# cslr_emif_001 register map
Vendor: Texas Instruments
Peripheral module from a debugger description file (folder C5515).
Address unit: 16 bits
Registers are 16-bit, access not given, reset 0x0 unless marked. A register's access mark holds for its fields unless they carry their own. Offsets are as the file gives them; lines under a group give offsets from that group; [hi:lo] are bit positions; {n}, {i} and the like mark numbered series; 'fields as' and 'values as' point back to an identical list; <NAME> marks a mode.

## EMIF — External Memory Interface
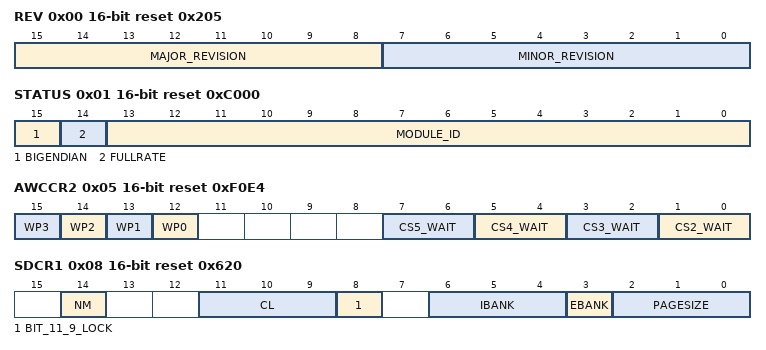
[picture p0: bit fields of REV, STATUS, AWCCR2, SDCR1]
0x00 REV ro reset 0x205 — Revision Register
  [15:8] MAJOR_REVISION — Major revision code for EMIF.
  [7:0] MINOR_REVISION — Minor revision code for EMIF.
0x01 STATUS ro reset 0xC000
  [15] BIGENDIAN — Big endian value, defining big endian mode (data R/W order)
    0=LITTLE (EMIF is running in little endian.); 1=BIG (EMIF is running in big endian.)
  [14] FULLRATE — Full rate status bit. This bit reflects the clock rate being used by the EMIF.
    0=HALFRATE (EMIF is running at half the CPU clock frequency.); 1=FULLRATE (EMIF is running at the same speed as the CPU clock.)
  [13:0] MODULE_ID — Module ID code for EMIF.
0x04 AWCCR1 reset 0x40 — Asynchronous Wait Cycle Configuration Register 1
  [7:0] MEWC rw — Maximum extended wait cycles. The EMIF will wait for a maximum of (MEWC + 1) x 16 clock cycles before it stops inserting asynchronous wait cycles and procedes to the hold period of the access. This setting applies to all the wait pins.
0x05 AWCCR2 reset 0xF0E4 — Asynchronous Wait Cycle Configuration Register 2
  [n+12] WP{n} rw (n=0..3) — EM_WAIT{n} polarity bit. This bit defines the polarity of the EM_WAIT{n} pin.
    0=LOW (Insert wait cycles if wait pin is low.); 1=HIGH (Insert wait cycles if wait pin is high.)
  [2n-3:2n-4] CS{n}_WAIT rw (n=2..5) — Wait pin mapping bits for EMIF CS{n}. By default, each asynchronous chip select space is assigned a wait input pin. You can use the wait pin mapping bits to change the default assignment.
    {v}=WAIT{v} (Use the EM_WAIT{v} pin.) (v=0..3)
0x08 SDCR1 reset 0x620 — SDRAM Configuration Register 1
  [14] NM rw — Narrow mode bit. This bit should always be set to 1. A write to this field will cause the EMIF to start the SDRAM initialization sequence.
  [11:9] CL rw — CAS latency. This field defines the CAS latency to be used when accessing connected SDRAM devices. A 1 must be simultaniously written to the BIT_11_9_LOCK bit field of this register in order to write to the CL bit field. Writing to this field triggers the SDRAM initialization sequence.
    0=RSV0 (Reserved.); 1=RSV1 (Reserved.); 2=TWO (CAS latency set to 2 EM_SDCLK cycles.); 3=THREE (CAS latency set to 3 EM_SDCLK cycles.); {v}=RSV{v} (Reserved.) (v=4..7)
  [8] BIT_11_9_LOCK rw — Bits 11 to 9 lock. CL can only be written if BIT_11_9_LOCK is simultaniously written with a 1. BIT_11_9_LOCK is always read as 0.
    0=NOWRITES (Writes to bits 11 through 9 are disabled.); 1=WRITES (Writes to bits 11 through 9 are enabled.)
  [6:4] IBANK rw — Internal SDRAM Bank size. This field defines number of banks inside the connected SDRAM devices. Writing to this field triggers the SDRAM initialization sequence.
    0=ONE (1 bank SDRAM devices.); 1=TWO (2 bank SDRAM devices.); 2=FOUR (4 bank SDRAM devices.); {v}=RSV{v} (Reserved.) (v=3..7)
  [3] EBANK rw — External chip select setup. Defines whether SDRAM accesses will use 1 or 2 chip select lines. A write to this field will cause the EMIF to start the SDRAM initialization sequence.
    0=ONE (EMIF will use SD_CE0 for all SDRAM accesses.); 1=TWO (EMIF will use SD_CE0 and SD_CE1 for all SDRAM accesses.)
  [2:0] PAGESIZE rw — Page size. This field defines the internal page size of connected SDRAM devices. Writing to this field triggers the SDRAM initialization sequence.
    0=EIGHT (8 column address bits (256 elements per row)); 1=NINE (9 column address bits (512 elements per row)); 2=TEN (10 column address bits (1024 elements per row)); 3=ELEVEN (11 column address bits (2048 elements per row)); {v}=RSV{v} (Reserved.) (v=4..7)
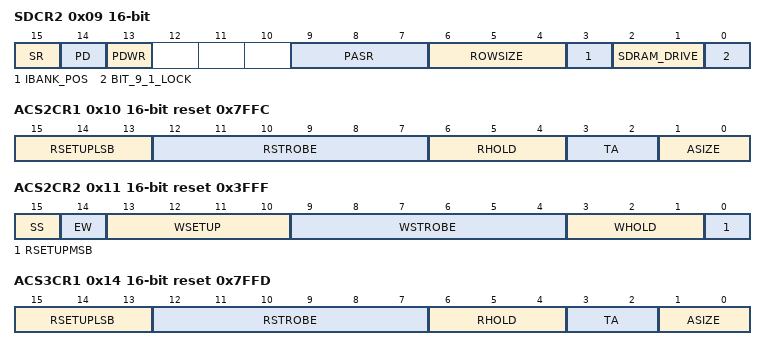
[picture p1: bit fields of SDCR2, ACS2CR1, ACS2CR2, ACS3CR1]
0x09 SDCR2 — SDRAM Configuration Register 2
  [15] SR rw — Self-Refresh mode bit. This bit controls entering and exiting of the Self-Refresh mode. The field should be written using a byte-write to the upper byte of SDCR to avoid triggering the SDRAM initialization sequence.
    0=EXIT (Writing a 0 to this bit will cause connected SDRAM devices and the EMIF to exit the self-refresh mode.); 1=ENTER (Writing a 1 to this bit will cause connected SDRAM devices and the EMIF to enter the self-refresh mode.)
  [14] PD rw — Power down bit. This bit controls entering and exiting of the power down mode. The field should be written using a byte-write to the upper byte of SDCR to avoid triggering the SDRAM initialization sequence. If both SR and PD bits are set, the EMIF will go into Self Refresh.
    0=EXIT (Writing a 0 to this bit will cause connected SDRAM devices and the EMIF to exit the power down mode.); 1=ENTER (Writing a 1 to this bit will cause connected SDRAM devices and the EMIF to enter the power down mode.)
  [13] PDWR rw — Perform refreshes during power down bit. Writign a 1 to this bit will cause EMIF to exit powerdown state and issue and AUTO REFRESH command every time Refresh May level is set.
    0=NOREFR (Do not perform refreshes during power down.); 1=REFR (Perform refreshes during power down.)
  [9:7] PASR rw — Partial array self refresh. These bits get loaded into the Extended Mode Register of a mobile SDR during initialization. A write to this field will cause the EMIF to start the SDRAM initialization sequence. To write to this field you must simultaneously set BIT_9_1_LOCK to 1.
    0=FOUR (4 banks will be refreshed.); 1=TWO (2 banks will be refreshed.); 2=ONE (1 bank will be refreshed.); 3=RSV3 (Reserved.); 4=RSV4 (Reserved.); 5=HALF (Half a bank will be refreshed.); 6=QUARTER (One quarter of a bank will be refreshed.); 7=RSV7 (Reserved.)
  [6:4] ROWSIZE rw — Row size. Defines the number of row address bits of connected SDRAM devices. This field is only used when IBANK_POS is set to 1. A write to this field will cause the EMIF to start the SDRAM initialization sequence. To write to this field you must simultaneously set BIT_9_1_LOCK to 1.
    0=NINE (9 row address bits.); 1=TEN (10 row address bits.); 2=ELEVEN (11 row address bits.); 3=TWELVE (12 row address bits.); 4=THIRTEEN (13 row address bits.); 5=FOURTEEN (14 row address bits.); 6=RSV6 (Reserved.); 7=RSV7 (Reserved.)
  [3] IBANK_POS rw — Internal bank position. This bit specifies the mapping of the logical address to the SDRAM address. A write to this field will cause the EMIF to start the SDRAM initialization sequence. To write to this field you must simultaneously set BIT_9_1_LOCK to 1.
  [2:1] SDRAM_DRIVE rw — SDRAM drive strength. These bits specify the the SDRAM drive strength configuration the EMIF uses while initializing the SDRAM device. A write to this field will cause the EMIF to start the SDRAM initialization sequence. To write to this field you must simultaneously set BIT_9_1_LOCK to 1.
    0=FULL (Full drive strength.); 1=HALF (Half drive strength.); 2=QUARTER (One fourth drive strength.); 3=EIGTH (One eigth drive strength.)
  [0] BIT_9_1_LOCK rw — Bits 9 to 1 lock. Bits 9 through 1 can only be written if BIT_9_1_LOCK is simultaneously written with a 1. BIT_9_1_LOCK is always read as a 0.
    0=NOWRITES (Writes to bits 9 through 1 are disabled.); 1=WRITES (Writes to bits 9 through 1 are enabled.)
0x0C SDRCR reset 0x7D — SDRAM Refresh Control Register
  [12:0] REFRATE rw — Refresh Rate. This field is used to define the SDRAM refresh period in terms of EM_SDCLK cycles. Writing a value < 0x0020 to this field will cause it to be loaded with (2 * T_RFC) + 1 value from SDRAM timing register.
0x10 ACS2CR1 rw reset 0x7FFC — Asynchronous CS2 Configuration Register 1
  [15:13] RSETUPLSB — These bits in conjuction with RSETUPMSB in NCE0CR2 define the read setup timing in EM_SDCLK cycles, minus one cycle.
  [12:7] RSTROBE — Read strobe width in EM_SDCLK cycles, minus one cycle.
  [6:4] RHOLD — Read hold width in EM_SDCLK cycles, minus one cycle.
  [3:2] TA — Minimum turn-around time. This field defines the minimum number of EM_SDCLK cycles between reads and writes, minus one cycle.
  [1:0] ASIZE — Asynchronous data bus width. This field defines the width of the asynchronous device's data bus.
    0=EIGHTBIT (8-bit data bus.); 1=SIXTEENBIT (16-bit data bus.); 2=RSV2 (Reserved.); 3=RSV3 (Reserved.)
0x11 ACS2CR2 rw reset 0x3FFF — Asynchronous CS2 Configuration Register 2
  [15] SS — Select Strobe bit. This bit defines whether the asynchronous interface operates in WE Strobe Mode or Select Strobe Mode.
    0=ENABLED (WE Strobe Mode enabled.); 1=DISABLED (Select Strobe Mode enabled.)
  [14] EW — Extended wait cycles enable bit. This bit defines whether extended wait cycles will be enabled.
    0=DISABLED (Extended wait cycles disabled.); 1=ENABLED (Extended wait cycles enabled.)
  [13:10] WSETUP — Write setup width in EM_SDCLK cycles, minus one cycle.
  [9:4] WSTROBE — Write strobe width in EM_SDCLK cycles, minus one cycle.
  [3:1] WHOLD — Write hold width in EM_SDCLK cycles, minus one cycle.
  [0] RSETUPMSB — These bits in conjuction with RSETUPLSB in NCE0CR1 define the read setup timing in EM_SDCLK cycles, minus one cycle.
0x14 ACS3CR1 rw reset 0x7FFD — Asynchronous CS3 Configuration Register 1
  [15:13] RSETUPLSB — These bits in conjuction with RSETUPMSB in NCE1CR2 define the read setup timing in EM_SDCLK cycles, minus one cycle.
  [12:7] RSTROBE — Read strobe width in EM_SDCLK cycles, minus one cycle.
  [6:4] RHOLD — Read hold width in EM_SDCLK cycles, minus one cycle.
  [3:2] TA — Minimum turn-around time. This field defines the minimum number of EM_SDCLK cycles between reads and writes, minus one cycle.
  [1:0] ASIZE — Asynchronous data bus width. This field defines the width of the asynchronous device's data bus.
    values as ACS2CR1.ASIZE
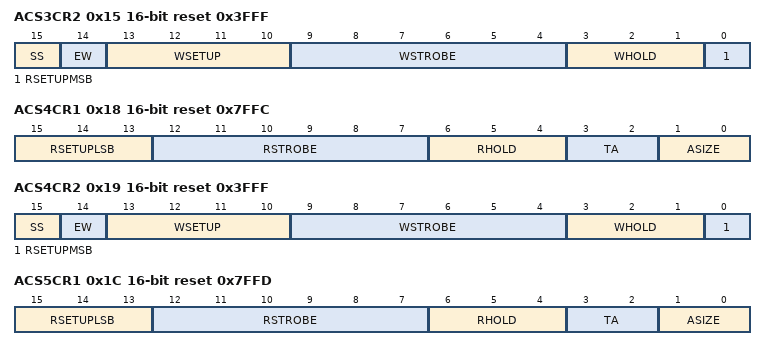
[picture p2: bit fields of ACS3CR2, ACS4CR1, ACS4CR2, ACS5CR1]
0x15 ACS3CR2 rw reset 0x3FFF — Asynchronous CS3 Configuration Register 2
  [15] SS — Select Strobe bit. This bit defines whether the asynchronous interface operates in WE Strobe Mode or Select Strobe Mode.
    values as ACS2CR2.SS
  [14] EW — Extended wait cycles enable bit. This bit defines whether extended wait cycles will be enabled.
    values as ACS2CR2.EW
  [13:10] WSETUP — Write setup width in EM_SDCLK cycles, minus one cycle.
  [9:4] WSTROBE — Write strobe width in EM_SDCLK cycles, minus one cycle.
  [3:1] WHOLD — Write hold width in EM_SDCLK cycles, minus one cycle.
  [0] RSETUPMSB — These bits in conjuction with RSETUPLSB in NCE1CR1 define the read setup timing in EM_SDCLK cycles, minus one cycle.
0x18 ACS4CR1 rw reset 0x7FFC — Asynchronous CS4 Configuration Register 1
  [15:13] RSETUPLSB — These bits in conjuction with RSETUPMSB in ACE0CR2 define the read setup timing in EM_SDCLK cycles, minus one cycle.
  [12:7] RSTROBE — Read strobe width in EM_SDCLK cycles, minus one cycle.
  [6:4] RHOLD — Read hold width in EM_SDCLK cycles, minus one cycle.
  [3:2] TA — Minimum turn-around time. This field defines the minimum number of EM_SDCLK cycles between reads and writes, minus one cycle.
  [1:0] ASIZE — Asynchronous data bus width. This field defines the width of the asynchronous device's data bus.
    values as ACS2CR1.ASIZE
0x19 ACS4CR2 rw reset 0x3FFF — Asynchronous CE0 Configuration Register 2
  [15] SS — Select Strobe bit. This bit defines whether the asynchronous interface operates in WE Strobe Mode or Select Strobe Mode.
    values as ACS2CR2.SS
  [14] EW — Extended wait cycles enable bit. This bit defines whether extended wait cycles will be enabled.
    values as ACS2CR2.EW
  [13:10] WSETUP — Write setup width in EM_SDCLK cycles, minus one cycle.
  [9:4] WSTROBE — Write strobe width in EM_SDCLK cycles, minus one cycle.
  [3:1] WHOLD — Write hold width in EM_SDCLK cycles, minus one cycle.
  [0] RSETUPMSB — These bits in conjuction with RSETUPLSB in ACE0CR1 define the read setup timing in EM_SDCLK cycles, minus one cycle.
0x1C ACS5CR1 rw reset 0x7FFD — Asynchronous CS5 Configuration Register 1
  [15:13] RSETUPLSB — These bits in conjuction with RSETUPMSB in ACE1CR2 define the read setup timing in EM_SDCLK cycles, minus one cycle.
  [12:7] RSTROBE — Read strobe width in EM_SDCLK cycles, minus one cycle.
  [6:4] RHOLD — Read hold width in EM_SDCLK cycles, minus one cycle.
  [3:2] TA — Minimum turn-around time. This field defines the minimum number of EM_SDCLK cycles between reads and writes, minus one cycle.
  [1:0] ASIZE — Asynchronous data bus width. This field defines the width of the asynchronous device's data bus.
    values as ACS2CR1.ASIZE
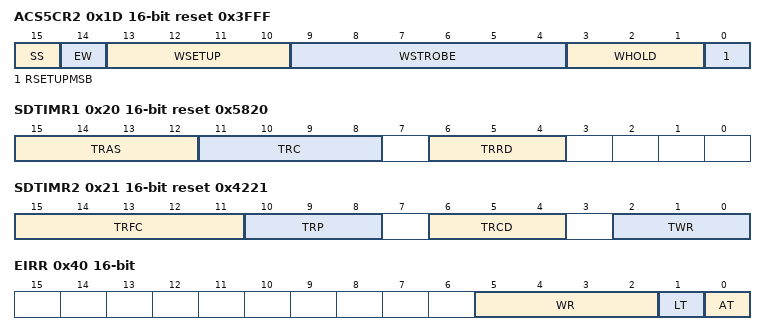
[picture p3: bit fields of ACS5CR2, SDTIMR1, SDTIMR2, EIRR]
0x1D ACS5CR2 rw reset 0x3FFF — Asynchronous CS5 Configuration Register 2
  [15] SS — Select Strobe bit. This bit defines whether the asynchronous interface operates in WE Strobe Mode or Select Strobe Mode.
    values as ACS2CR2.SS
  [14] EW — Extended wait cycles enable bit. This bit defines whether extended wait cycles will be enabled.
    values as ACS2CR2.EW
  [13:10] WSETUP — Write setup width in EM_SDCLK cycles, minus one cycle.
  [9:4] WSTROBE — Write strobe width in EM_SDCLK cycles, minus one cycle.
  [3:1] WHOLD — Write hold width in EM_SDCLK cycles, minus one cycle.
  [0] RSETUPMSB — These bits in conjuction with RSETUPLSB in ACE1CR1 define the read setup timing in EM_SDCLK cycles, minus one cycle.
0x20 SDTIMR1 reset 0x5820 — SDRAM Timing Register 1
  [15:12] TRAS rw — Specifies the Tras value of the SDRAM. This defines the minimum number of EM_SDCLK clock cycles from Activate (ACTV) to Precharge (PRE), minus 1: T_RAS = (Tras/tEM_SDCLK) - 1
  [11:8] TRC rw — Specifies the Trc value of the SDRAM. This defines the minimum number of EM_SDCLK clock cycles from Activate (ACTV) to Activate (ACTV), minus 1: T_RC = (Trc/tEM_SDCLK) - 1
  [6:4] TRRD rw — Specifies the Trrd value of the SDRAM. This defines the minimum number of EM_SDCLK clock cycles from Activate (ACTV) to Activate (ACTV) for a different bank, minus 1: T_RRD = (Trrd/tEM_SDCLK) - 1
0x21 SDTIMR2 reset 0x4221 — SDRAM Timing Register 1
  [15:11] TRFC rw — Specifies the Trfc value of the SDRAM. This defines the minimum number of EM_SDCLK cycles from Refresh (REFR) to Refresh (REFR), minus 1: T_RFC = (Trfc/tEM_SDCLK) - 1
  [10:8] TRP rw — Specifies the Trp value of the SDRAM. This defines the minimum number of EM_SDCLK cycles from Precharge (PRE) to Activate (ACTV) or Refresh (REFR) command, minus 1: T_RP = (Trp/tEM_SDCLK) - 1
  [6:4] TRCD rw — Specifies the Trcd value of the SDRAM. This defines the minimum number of EM_SDCLK cycles from Active (ACTV) to Read (READ) or Write (WRT), minus 1: T_RCD = (Trcd/tEM_SDCLK) - 1
  [2:0] TWR rw — Specifies the Twr value of the SDRAM. This defines the minimum number of EM_SDCLK cycles from last Write (WRT) to Precharge (PRE), minus 1: T_WR = (Twr/tEM_SDCLK) - 1
0x3C SDSRETR reset 0x5 — SDRAM Self Refresh Exit Timing Register
  [4:0] TXS rw — This field specifies the minimum number of EM_SDCLK cycles from Self-Refresh exit to any command, minus one. T_XS = Txsr / tEM_SDCLK - 1
0x40 EIRR — Interrupt Raw Register
  [5:2] WR — Wait rise bits. These bits are set to 1 by hardware when a rising edge is detected on the wait pins. The polarity bits of AWCCR2 have not effect on these bits. Writing a 1 will clear these bits as well as the WRMASKED bits in the interrupt masked register (EMIR). Writing a 0 has no effect. (access R/W1C)
  [1] LT — Line trap. These bits are set to 1 by hardware to indicate illegal memory access. Writing a 1 will clear this bit as well as the LTMASKED bit in the interrupt masked register (EMIR). Writing a 0 has no effect. (access R/W1C)
  [0] AT — Asynchronous timeout. This bit is set to 1 by hardware to indicate that during an extended asynchronous memory access cycle, a wait pin did not go inactive within the number of cycles defined by the MEWC field in asynchronous wait cycle configuration register 1 (AWCCR1). Writing a 1 will clear these bits as well as the ATMASKED bit in the interrupt masked register (EMIR). Writing a 0 has no effect. (access R/W1C)
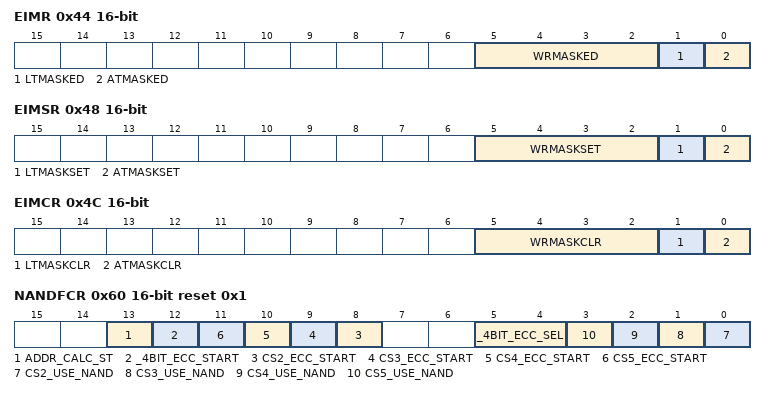
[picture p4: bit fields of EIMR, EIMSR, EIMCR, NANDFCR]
0x44 EIMR — Interrupt Mask Register
  [5:2] WRMASKED — Masked wait rise. These bits are set to 1 by hardware when a rising edge is detected on the wait pins. The polarity bits of AWCCR2 have not effect on these bits. Writing a 1 will clear these bits as well as the WR bits in the interrupt raw register (EIRR). Writing a 0 has no effect. (access R/W1C)
  [1] LTMASKED — Masked line trap. These bits are set to 1 by hardware to indicate illegal memory access, only if the LTMASKSET bit in the interrupt mask set register (EIMSR) is set to 1. Writing a 1 will clear these bits as well as the LT bit in the interrupt raw register (EIRR). Writing a 0 has no effect. (access R/W1C)
  [0] ATMASKED — Masked asynchronous timeout. This bit is set to 1 by hardware to indicate that during an extended asynchronous memory access cycle, a wait pin did not go inactive within the number of cycles defined by the MEWC field in asynchronous wait cycle configuration register 1 (AWCCR1), only if the ATMASKSET bit in the interrupt mask set register (EIMSR) is set to 1. Writing a 1 will clear these bits as well as the AT bit in the interrupt raw register (EIRR). Writing a 0 has no effect. (access R/W1C)
0x48 EIMSR — Interrupt Mask Set Register
  [5:2] WRMASKSET — Mask set for WRMASKED bits in interrupt mask register (EIMR). Writing a 1 will enable the wait rise interrupts and set these bits as well as the WRMASKCLR bits in the interrupt mask clear register (EIMCR). Writing a 0 has no effect. (access R/W1S)
  [1] LTMASKSET — Mask set for LTMASKED bit in interrupt mask register (EIMR). Writing a 1 will enable the interrupt and set this bit as well as the LTMASKCLR bit in the interrupt mask clear register (EIMCR). Writing a 0 has no effect. (access R/W1S)
  [0] ATMASKSET — Mask set for ATMASKED bit in interrupt mask register (EIMR). Writing a 1 will enable the interrupt and set this bit as well as the ATMASKCLR bit in the interrupt mask clear register (EIMCR). Writing a 0 has no effect. (access R/W1S)
0x4C EIMCR — Interrupt Mask clear Register
  [5:2] WRMASKCLR — Mask clear for WRMASKED bits in interrupt mask register (EIMR). Writing a 1 will disable the wait rise interrupts and clear these bits as well as the WRMASKSET bits in the interrupt mask set register (EIMSR). Writing a 0 has no effect. (access R/W1C)
  [1] LTMASKCLR — Mask clear for LTMASKED bit in interrupt mask register (EIMR). Writing a 1 will disable the interrupt and clear this bit as well as the LTMASKSET bit in the interrupt mask set register (EIMSR). Writing a 0 has no effect. (access R/W1C)
  [0] ATMASKCLR — Mask clear for ATMASKED bit in interrupt mask register (EIMR). Writing a 1 will disable the interrupt and clear this bit as well as the ATMASKSET bit in the interrupt mask set register (EIMSR). Writing a 0 has no effect. (access R/W1C)
0x60 NANDFCR reset 0x1 — NAND Flash Control Register
  [13] ADDR_CALC_ST rw — NAND flash 4-bit ECC error address and error value calculation start. Set to 1 to start 4-bit ECC error address and error value calculation on read syndrome. This bit is cleared when any of the NAND flash error addres registers or NAND flash error value registers are read. Writing a 0 has no effect.
  [12] _4BIT_ECC_START rw — NAND flash 4-bit ECC start for the selected chip select. Set to 1 to start 4-bit ECC calculation on data for NAND flash on chip select selected by 4BIT_ECC_SEL field. This bit is cleared when any of the NAND flash 4-Bit ECC registers are read. Writing a 0 has no effect.
  [n+6] CS{n}_ECC_START rw (n=2..5) — NAND flash 1-bit ECC start for EMIF CS{n}. Set to 1 to start 1-bit ECC calculation on data for NAND flash on EMIF CS{n}. This bit is cleared when NAND flash CS{n} 1-Bit ECC register is read. Writing a 0 has no effect.
  [5:4] _4BIT_ECC_SEL rw — NAND flash 4-bit ECC chip select selection. This field selects the chip select on which the 4-bit ECC will be calculated.
    {v}=CS{v+2} (Select EMIF CS{v+2} for 4-bit ECC calculation.) (v=0..3)
  [n-2] CS{n}_USE_NAND rw (n=2..5) — NAND flash mode for EM_CS{n}. Set to 1 if using NAND flash on EM_CS{n}.
    0=NONAND (Not using NAND flash.); 1=NAND (Using NAND flash on chip select pin.)
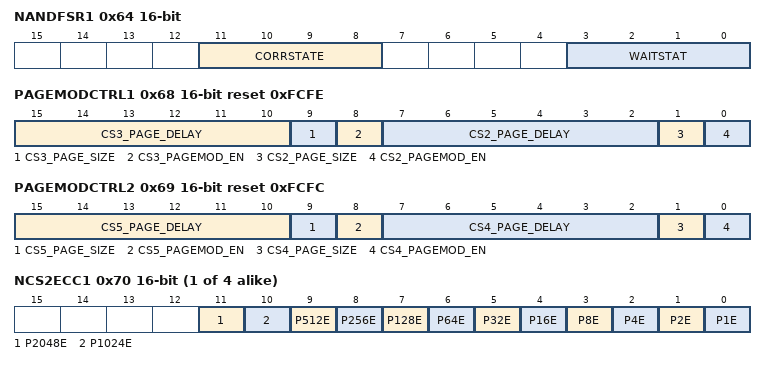
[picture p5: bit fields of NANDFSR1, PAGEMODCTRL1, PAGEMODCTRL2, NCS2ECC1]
0x64 NANDFSR1 — NAND Flash Status Register 1
  [11:8] CORRSTATE ro — 4-bit ECC state value when performing error address and error value calculation.
  [3:0] WAITSTAT ro — These bits shows the raw status of the four wait input signals (EM_WAIT[3:0]). The polarity bits in the asynchronous wait cycle configuration register 2 (AWCCR2) have no effect on these bits. WAITSTAT[0] corresponds to EM_WAIT[0], WAITSTAT[1] to EM_WAIT[1], and so on.
0x65 NANDFSR2 — NAND Flash Status Register 2
  [1:0] ERRNUM ro — 4-bit ECC error number. This field shows the number for errors found after the error address calculation and error value calculation is done.
    0=ERR1 (1 error found.); 1=ERR2 (2 errors found.); 2=ERR3 (3 errors found.); 3=ERR4 (4 errors found.)
0x68 PAGEMODCTRL1 rw reset 0xFCFE — Page Mode Control Register 1
  [15:10] CS3_PAGE_DELAY — Page access delay for NOR flash connected on EM_CS3. Number of EMIF clock cycles required for the page read data to be valid, minus one cycle. This value must not be set to 0.
  [9] CS3_PAGE_SIZE — Page size for NOR flash connected on EM_CS3.
    0=FOUR (4-word page.); 1=EIGHT (8-word page.)
  [8] CS3_PAGEMOD_EN — Page mode enable for NOR flash connected on EM_CS3.
    0=DISABLE (Disable page mode.); 1=ENABLE (Enable page mode.)
  [7:2] CS2_PAGE_DELAY — Page access delay for NOR flash connected on EM_CS2. Number of EMIF clock cycles required for the page read data to be valid, minus one cycle. This value must not be set to 0.
  [1] CS2_PAGE_SIZE — Page size for NOR flash connected on EM_CS2.
    0=FOUR (4-word page.); 1=EIGHT (8-word page.)
  [0] CS2_PAGEMOD_EN — Page mode enable for NOR flash connected on EM_CS2.
    0=DISABLE (Disable page mode.); 1=ENABLE (Enable page mode.)
0x69 PAGEMODCTRL2 rw reset 0xFCFC — Page Mode Control Register 2
  [15:10] CS5_PAGE_DELAY — Page access delay for NOR flash connected on EM_CS5. Number of EMIF clock cycles required for the page read data to be valid, minus one cycle. This value must not be set to 0.
  [9] CS5_PAGE_SIZE — Page size for NOR flash connected on EM_CS5.
    0=FOUR (4-word page.); 1=EIGHT (8-word page.)
  [8] CS5_PAGEMOD_EN — Page mode enable for NOR flash connected on EM_CS5.
    0=DISABLE (Disable page mode.); 1=ENABLE (Enable page mode.)
  [7:2] CS4_PAGE_DELAY — Page access delay for NOR flash connected on EM_CS4. Number of EMIF clock cycles required for the page read data to be valid, minus one cycle. This value must not be set to 0.
  [1] CS4_PAGE_SIZE — Page size for NOR flash connected on EM_CS4.
    0=FOUR (4-word page.); 1=EIGHT (8-word page.)
  [0] CS4_PAGEMOD_EN — Page mode enable for NOR flash connected on EM_CS4.
    0=DISABLE (Disable page mode.); 1=ENABLE (Enable page mode.)
{0x68+4i} NCS{i}ECC1 (i=2..5) — NAND Flash CS{i} 1-Bit ECC Register 1
  [11] P2048E rw — 1-Bit ECC code calculated while reading/writing NAND Flash. For 8-bit NAND Flash, P1E, P2E, and P4E are column parities and P8E to P2048E are row parities. For 16-bit NAND Flash, P1E, P2E, P4E, and P8E are column parities and P16E to P2048E are row parities.
  [10] P1024E rw — 1-Bit ECC code calculated while reading/writing NAND Flash. For 8-bit NAND Flash, P1E, P2E, and P4E are column parities and P8E to P2048E are row parities. For 16-bit NAND Flash, P1E, P2E, P4E, and P8E are column parities and P16E to P2048E are row parities.
  [9] P512E rw — 1-Bit ECC code calculated while reading/writing NAND Flash. For 8-bit NAND Flash, P1E, P2E, and P4E are column parities and P8E to P2048E are row parities. For 16-bit NAND Flash, P1E, P2E, P4E, and P8E are column parities and P16E to P2048E are row parities.
  [8] P256E rw — 1-Bit ECC code calculated while reading/writing NAND Flash. For 8-bit NAND Flash, P1E, P2E, and P4E are column parities and P8E to P2048E are row parities. For 16-bit NAND Flash, P1E, P2E, P4E, and P8E are column parities and P16E to P2048E are row parities.
  [7] P128E rw — 1-Bit ECC code calculated while reading/writing NAND Flash. For 8-bit NAND Flash, P1E, P2E, and P4E are column parities and P8E to P2048E are row parities. For 16-bit NAND Flash, P1E, P2E, P4E, and P8E are column parities and P16E to P2048E are row parities.
  [6] P64E rw — 1-Bit ECC code calculated while reading/writing NAND Flash. For 8-bit NAND Flash, P1E, P2E, and P4E are column parities and P8E to P2048E are row parities. For 16-bit NAND Flash, P1E, P2E, P4E, and P8E are column parities and P16E to P2048E are row parities.
  [5] P32E rw — 1-Bit ECC code calculated while reading/writing NAND Flash. For 8-bit NAND Flash, P1E, P2E, and P4E are column parities and P8E to P2048E are row parities. For 16-bit NAND Flash, P1E, P2E, P4E, and P8E are column parities and P16E to P2048E are row parities.
  [4] P16E rw — 1-Bit ECC code calculated while reading/writing NAND Flash. For 8-bit NAND Flash, P1E, P2E, and P4E are column parities and P8E to P2048E are row parities. For 16-bit NAND Flash, P1E, P2E, P4E, and P8E are column parities and P16E to P2048E are row parities.
  [3] P8E rw — 1-Bit ECC code calculated while reading/writing NAND Flash. For 8-bit NAND Flash, P1E, P2E, and P4E are column parities and P8E to P2048E are row parities. For 16-bit NAND Flash, P1E, P2E, P4E, and P8E are column parities and P16E to P2048E are row parities.
  [2] P4E rw — 1-Bit ECC code calculated while reading/writing NAND Flash. For 8-bit NAND Flash, P1E, P2E, and P4E are column parities and P8E to P2048E are row parities. For 16-bit NAND Flash, P1E, P2E, P4E, and P8E are column parities and P16E to P2048E are row parities.
  [1] P2E rw — 1-Bit ECC code calculated while reading/writing NAND Flash. For 8-bit NAND Flash, P1E, P2E, and P4E are column parities and P8E to P2048E are row parities. For 16-bit NAND Flash, P1E, P2E, P4E, and P8E are column parities and P16E to P2048E are row parities.
  [0] P1E rw — 1-Bit ECC code calculated while reading/writing NAND Flash. For 8-bit NAND Flash, P1E, P2E, and P4E are column parities and P8E to P2048E are row parities. For 16-bit NAND Flash, P1E, P2E, P4E, and P8E are column parities and P16E to P2048E are row parities.
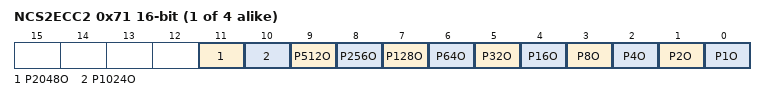
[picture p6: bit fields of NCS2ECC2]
{0x69+4i} NCS{i}ECC2 (i=2..5) — NAND Flash CS{i} 1-Bit ECC Register 2
  [11] P2048O rw — 1-Bit ECC code calculated while reading/writing NAND Flash. For 8-bit NAND Flash, P1O, P2O, and P4O are column parities and P8O to P2048O are row parities. For 16-bit NAND Flash, P1O, P2O, P4O, and P8O are column parities and P16O to P2048O are row parities.
  [10] P1024O rw — 1-Bit ECC code calculated while reading/writing NAND Flash. For 8-bit NAND Flash, P1O, P2O, and P4O are column parities and P8O to P2048O are row parities. For 16-bit NAND Flash, P1O, P2O, P4O, and P8O are column parities and P16O to P2048O are row parities.
  [9] P512O rw — 1-Bit ECC code calculated while reading/writing NAND Flash. For 8-bit NAND Flash, P1O, P2O, and P4O are column parities and P8O to P2048O are row parities. For 16-bit NAND Flash, P1O, P2O, P4O, and P8O are column parities and P16O to P2048O are row parities.
  [8] P256O rw — 1-Bit ECC code calculated while reading/writing NAND Flash. For 8-bit NAND Flash, P1O, P2O, and P4O are column parities and P8O to P2048O are row parities. For 16-bit NAND Flash, P1O, P2O, P4O, and P8O are column parities and P16O to P2048O are row parities.
  [7] P128O rw — 1-Bit ECC code calculated while reading/writing NAND Flash. For 8-bit NAND Flash, P1O, P2O, and P4O are column parities and P8O to P2048O are row parities. For 16-bit NAND Flash, P1O, P2O, P4O, and P8O are column parities and P16O to P2048O are row parities.
  [6] P64O rw — 1-Bit ECC code calculated while reading/writing NAND Flash. For 8-bit NAND Flash, P1O, P2O, and P4O are column parities and P8O to P2048O are row parities. For 16-bit NAND Flash, P1O, P2O, P4O, and P8O are column parities and P16O to P2048O are row parities.
  [5] P32O rw — 1-Bit ECC code calculated while reading/writing NAND Flash. For 8-bit NAND Flash, P1O, P2O, and P4O are column parities and P8O to P2048O are row parities. For 16-bit NAND Flash, P1O, P2O, P4O, and P8O are column parities and P16O to P2048O are row parities.
  [4] P16O rw — 1-Bit ECC code calculated while reading/writing NAND Flash. For 8-bit NAND Flash, P1O, P2O, and P4O are column parities and P8O to P2048O are row parities. For 16-bit NAND Flash, P1O, P2O, P4O, and P8O are column parities and P16O to P2048O are row parities.
  [3] P8O rw — 1-Bit ECC code calculated while reading/writing NAND Flash. For 8-bit NAND Flash, P1O, P2O, and P4O are column parities and P8O to P2048O are row parities. For 16-bit NAND Flash, P1O, P2O, P4O, and P8O are column parities and P16O to P2048O are row parities.
  [2] P4O rw — 1-Bit ECC code calculated while reading/writing NAND Flash. For 8-bit NAND Flash, P1O, P2O, and P4O are column parities and P8O to P2048O are row parities. For 16-bit NAND Flash, P1O, P2O, P4O, and P8O are column parities and P16O to P2048O are row parities.
  [1] P2O rw — 1-Bit ECC code calculated while reading/writing NAND Flash. For 8-bit NAND Flash, P1O, P2O, and P4O are column parities and P8O to P2048O are row parities. For 16-bit NAND Flash, P1O, P2O, P4O, and P8O are column parities and P16O to P2048O are row parities.
  [0] P1O rw — 1-Bit ECC code calculated while reading/writing NAND Flash. For 8-bit NAND Flash, P1O, P2O, and P4O are column parities and P8O to P2048O are row parities. For 16-bit NAND Flash, P1O, P2O, P4O, and P8O are column parities and P16O to P2048O are row parities.
0xBC NAND4BITECCLOAD — NAND Flash 4-Bit ECC Load Register
  [9:0] _4BIT_ECC_LOAD rw — 4-Bit ECC Load. This register is used to load 4-bit ECC values when performing syndrome calculation during NAND Flash reads.
0xC0 NAND4BITECC1 — NAND Flash 4-Bit ECC Register 1
  [9:0] _4BIT_ECC_VAL1 ro — 4-Bit ECC or syndrome value 1 calculated while writing or reading NAND Flash.
0xC1 NAND4BITECC2 — NAND Flash 4-Bit ECC Register 2
  [9:0] _4BIT_ECC_VAL2 ro — 4-Bit ECC or syndrome value 2 calculated while writing or reading NAND Flash.
0xC4 NAND4BITECC3 — NAND Flash 4-Bit ECC Register 3
  [9:0] _4BIT_ECC_VAL3 ro — 4-Bit ECC or syndrome value 3 calculated while writing or reading NAND Flash.
0xC5 NAND4BITECC4 — NAND Flash 4-Bit ECC Register 4
  [9:0] _4BIT_ECC_VAL4 ro — 4-Bit ECC or syndrome value 4 calculated while writing or reading NAND Flash.
0xC8 NAND4BITECC5 — NAND Flash 4-Bit ECC Register 5
  [9:0] _4BIT_ECC_VAL5 ro — 4-Bit ECC or syndrome value 5 calculated while writing or reading NAND Flash.
0xC9 NAND4BITECC6 — NAND Flash 4-Bit ECC Register 6
  [9:0] _4BIT_ECC_VAL6 ro — 4-Bit ECC or syndrome value 6 calculated while writing or reading NAND Flash.
0xCC NAND4BITECC7 — NAND Flash 4-Bit ECC Register 7
  [9:0] _4BIT_ECC_VAL7 ro — 4-Bit ECC or syndrome value 7 calculated while writing or reading NAND Flash.
0xCD NAND4BITECC8 — NAND Flash 4-Bit ECC Register 8
  [9:0] _4BIT_ECC_VAL8 ro — 4-Bit ECC or syndrome value 8 calculated while writing or reading NAND Flash.
0xD0 NANDERRADD1 — NAND Flash 4-Bit ECC Error Address Register 1
  [9:0] ERR_ADDR1 ro — 4-bit ECC error address 1.
0xD1 NANDERRADD2 — NAND Flash 4-Bit ECC Error Address Register 2
  [9:0] ERR_ADDR2 ro — 4-bit ECC error address 2.
0xD4 NANDERRADD3 — NAND Flash 4-Bit ECC Error Address Register 3
  [9:0] ERR_ADDR3 ro — 4-bit ECC error address 3.
0xD5 NANDERRADD4 — NAND Flash 4-Bit ECC Error Address Register 4
  [9:0] ERR_ADDR4 ro — 4-bit ECC error address 4.
0xD8 NANDERRVAL1 — NAND Flash 4-Bit ECC Error Value Register 1
  [9:0] ERR_VALUE1 ro — 4-bit ECC error value 1.
0xD9 NANDERRVAL2 — NAND Flash 4-Bit ECC Error Value Register 2
  [9:0] ERR_VALUE2 ro — 4-bit ECC error value 2.
0xDC NANDERRVAL3 — NAND Flash 4-Bit ECC Error Value Register 3
  [9:0] ERR_VALUE3 ro — 4-bit ECC error value 3.
0xDD NANDERRVAL4 — NAND Flash 4-Bit ECC Error Value Register 4
  [9:0] ERR_VALUE4 ro — 4-bit ECC error value 4.
